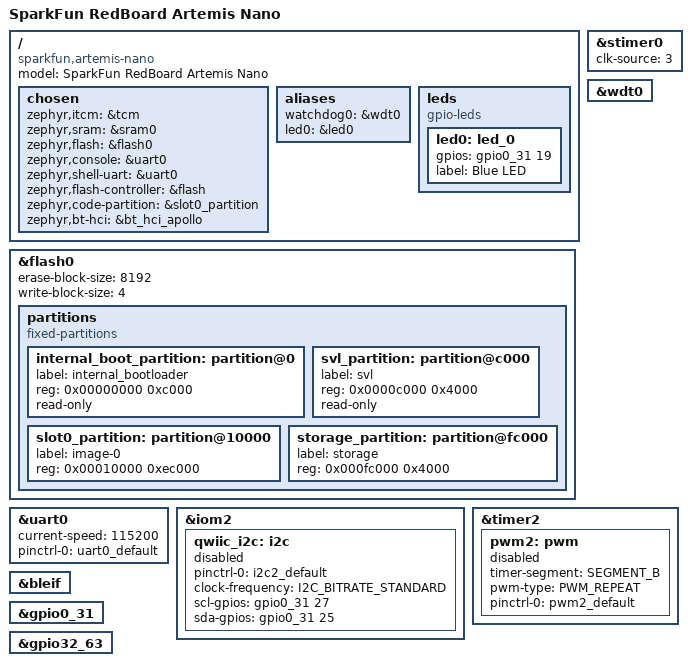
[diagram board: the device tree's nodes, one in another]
/*
 * SPDX-License-Identifier: Apache-2.0
 *
 * SparkFun RedBoard Artemis Nano (DEV-15443), Artemis module = Ambiq Apollo3 Blue.
 * Derived from boards/ambiq/apollo3_evb (Zephyr v4.4.2).
 */

/dts-v1/;
#include <ambiq/ambiq_apollo3_blue.dtsi>

#include "sparkfun_artemis_nano-pinctrl.dtsi"

/ {
	model = "SparkFun RedBoard Artemis Nano";
	compatible = "sparkfun,artemis-nano";

	chosen {
		zephyr,itcm = &tcm;
		zephyr,sram = &sram0;
		zephyr,flash = &flash0;
		zephyr,console = &uart0;
		zephyr,shell-uart = &uart0;
		zephyr,flash-controller = &flash;
		zephyr,code-partition = &slot0_partition;
		zephyr,bt-hci = &bt_hci_apollo;
	};

	aliases {
		watchdog0 = &wdt0;
		led0 = &led0;
	};

	leds {
		compatible = "gpio-leds";

		/* Blue LED D1 on pad 19 via 1k to GND: active high */
		led0: led_0 {
			gpios = <&gpio0_31 19 GPIO_ACTIVE_HIGH>;
			label = "Blue LED";
		};
	};
};

&flash0 {
	erase-block-size = <8192>;
	write-block-size = <4>;

	partitions {
		compatible = "fixed-partitions";
		#address-cells = <1>;
		#size-cells = <1>;

		/* Ambiq secure bootloader: never write */
		internal_boot_partition: partition@0 {
			label = "internal_bootloader";
			reg = <0x00000000 0xc000>;
			read-only;
		};

		/* SparkFun Variable Loader (SVL): USB recovery path, never write */
		svl_partition: partition@c000 {
			label = "svl";
			reg = <0x0000c000 0x4000>;
			read-only;
		};

		/* Application, linked here via CONFIG_FLASH_LOAD_OFFSET=0x10000 */
		slot0_partition: partition@10000 {
			label = "image-0";
			reg = <0x00010000 0xec000>;
		};

		/* 16 KB at the end of the 1 MB flash */
		storage_partition: partition@fc000 {
			label = "storage";
			reg = <0x000fc000 0x4000>;
		};
	};
};

&stimer0 {
	clk-source = <3>;
};

&uart0 {
	current-speed = <115200>;
	pinctrl-0 = <&uart0_default>;
	pinctrl-names = "default";
	status = "okay";
};

&wdt0 {
	status = "okay";
};

/* Qwiic connector, off until a phase needs it */
&iom2 {
	qwiic_i2c: i2c {
		pinctrl-0 = <&i2c2_default>;
		pinctrl-names = "default";
		clock-frequency = <I2C_BITRATE_STANDARD>;
		scl-gpios = <&gpio0_31 27 (GPIO_OPEN_DRAIN | GPIO_PULL_UP)>;
		sda-gpios = <&gpio0_31 25 (GPIO_OPEN_DRAIN | GPIO_PULL_UP)>;
		status = "disabled";
	};
};

/*
 * Servo PWM on D9 (pad 39), timer 2 segment B. Off for phase 2; phase 3 enables it
 * and moves timer 2 to the 3 MHz clock so a 20 ms frame (60000 counts) fits in 16 bits.
 */
&timer2 {
	pwm2: pwm {
		timer-segment = "SEGMENT_B";
		pwm-type = "PWM_REPEAT";
		pinctrl-0 = <&pwm2_default>;
		pinctrl-names = "default";
		status = "disabled";
	};
};

/*
 * BLE: the Apollo3 Blue radio sits inside the Artemis module behind the internal
 * BLEIF, so no pads are needed. The EVB's bleif_default pinmux (pads 30-33, 35, 41)
 * is only applied with CONFIG_SPI_AMBIQ_BLEIF_TIMING_TRACE, so it is left out here
 * and header pins A1/A5/A14/A15 stay free.
 */
&bleif {
	status = "okay";
};

&gpio0_31 {
	status = "okay";
};

&gpio32_63 {
	status = "okay";
};
